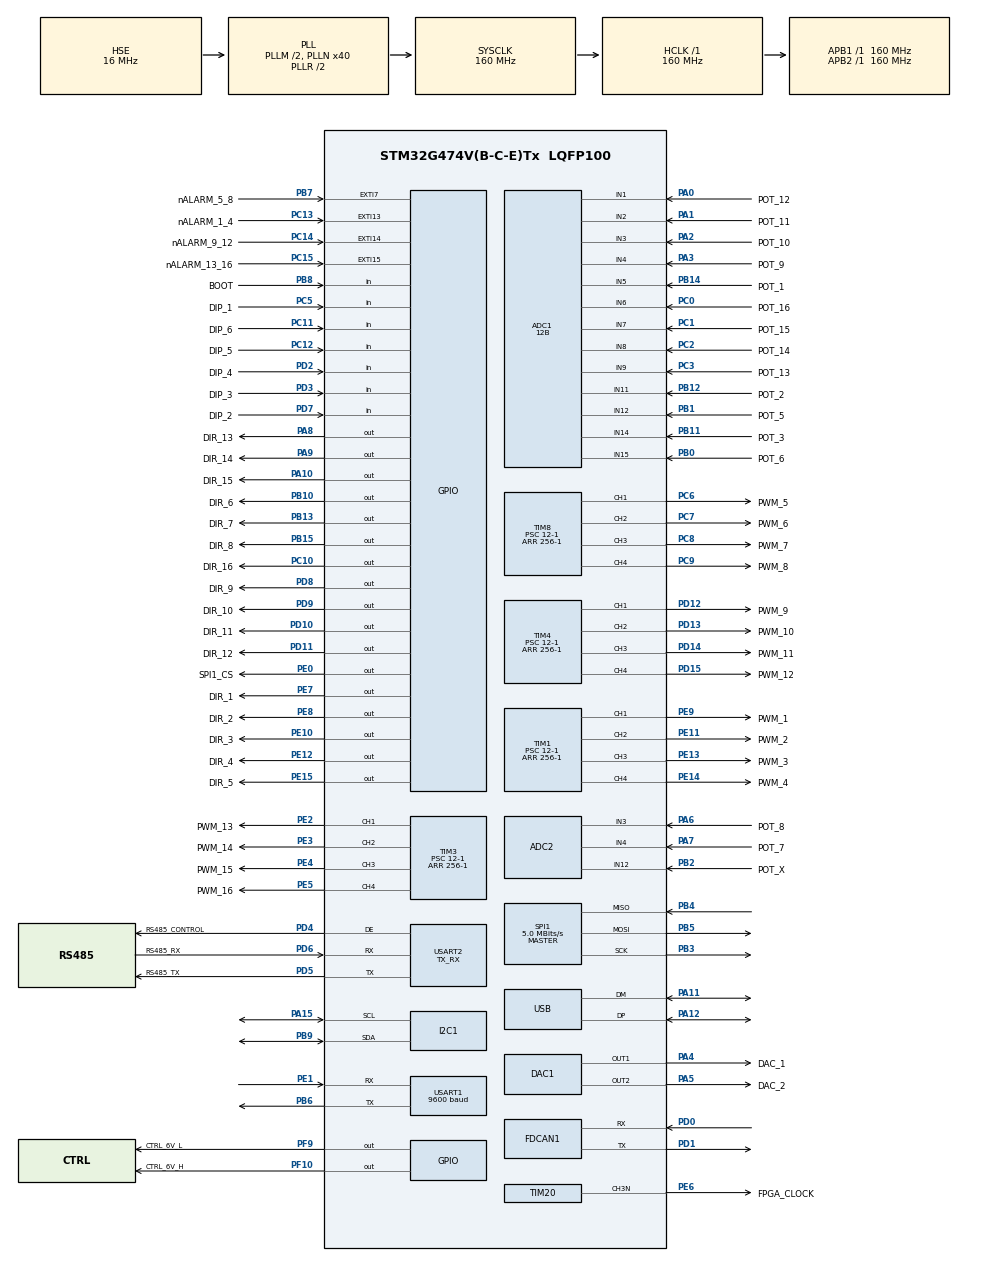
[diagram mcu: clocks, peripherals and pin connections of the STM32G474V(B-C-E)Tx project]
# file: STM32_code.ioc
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ADC1.Channel-0\#ChannelRegularConversion=ADC_CHANNEL_1
ADC1.Channel-1\#ChannelRegularConversion=ADC_CHANNEL_2
ADC1.Channel-10\#ChannelRegularConversion=ADC_CHANNEL_12
ADC1.Channel-11\#ChannelRegularConversion=ADC_CHANNEL_14
ADC1.Channel-12\#ChannelRegularConversion=ADC_CHANNEL_15
ADC1.Channel-2\#ChannelRegularConversion=ADC_CHANNEL_3
ADC1.Channel-3\#ChannelRegularConversion=ADC_CHANNEL_4
ADC1.Channel-4\#ChannelRegularConversion=ADC_CHANNEL_5
ADC1.Channel-5\#ChannelRegularConversion=ADC_CHANNEL_6
ADC1.Channel-6\#ChannelRegularConversion=ADC_CHANNEL_7
ADC1.Channel-7\#ChannelRegularConversion=ADC_CHANNEL_8
ADC1.Channel-8\#ChannelRegularConversion=ADC_CHANNEL_9
ADC1.Channel-9\#ChannelRegularConversion=ADC_CHANNEL_11
ADC1.ClockPrescaler=ADC_CLOCK_SYNC_PCLK_DIV4
ADC1.ContinuousConvMode=DISABLE
ADC1.DMAContinuousRequests=DISABLE
ADC1.EOCSelection=ADC_EOC_SEQ_CONV
ADC1.EnableInjectedConversion=DISABLE
ADC1.EnableRegularConversion=ENABLE
ADC1.NbrOfConversion=13
ADC1.NbrOfConversionFlag=1
ADC1.OffsetNumber-0\#ChannelRegularConversion=ADC_OFFSET_NONE
ADC1.OffsetNumber-1\#ChannelRegularConversion=ADC_OFFSET_NONE
ADC1.OffsetNumber-10\#ChannelRegularConversion=ADC_OFFSET_NONE
ADC1.OffsetNumber-11\#ChannelRegularConversion=ADC_OFFSET_NONE
ADC1.OffsetNumber-12\#ChannelRegularConversion=ADC_OFFSET_NONE
ADC1.OffsetNumber-2\#ChannelRegularConversion=ADC_OFFSET_NONE
ADC1.OffsetNumber-3\#ChannelRegularConversion=ADC_OFFSET_NONE
ADC1.OffsetNumber-4\#ChannelRegularConversion=ADC_OFFSET_NONE
ADC1.OffsetNumber-5\#ChannelRegularConversion=ADC_OFFSET_NONE
ADC1.OffsetNumber-6\#ChannelRegularConversion=ADC_OFFSET_NONE
ADC1.OffsetNumber-7\#ChannelRegularConversion=ADC_OFFSET_NONE
ADC1.OffsetNumber-8\#ChannelRegularConversion=ADC_OFFSET_NONE
ADC1.OffsetNumber-9\#ChannelRegularConversion=ADC_OFFSET_NONE
ADC1.Overrun=ADC_OVR_DATA_OVERWRITTEN
ADC1.Rank-0\#ChannelRegularConversion=1
ADC1.Rank-1\#ChannelRegularConversion=2
ADC1.Rank-10\#ChannelRegularConversion=11
ADC1.Rank-11\#ChannelRegularConversion=12
ADC1.Rank-12\#ChannelRegularConversion=13
ADC1.Rank-2\#ChannelRegularConversion=3
ADC1.Rank-3\#ChannelRegularConversion=4
ADC1.Rank-4\#ChannelRegularConversion=5
ADC1.Rank-5\#ChannelRegularConversion=6
ADC1.Rank-6\#ChannelRegularConversion=7
ADC1.Rank-7\#ChannelRegularConversion=8
ADC1.Rank-8\#ChannelRegularConversion=9
ADC1.Rank-9\#ChannelRegularConversion=10
ADC1.Resolution=ADC_RESOLUTION_12B
ADC1.SamplingTime-0\#ChannelRegularConversion=ADC_SAMPLETIME_24CYCLES_5
ADC1.SamplingTime-1\#ChannelRegularConversion=ADC_SAMPLETIME_24CYCLES_5
ADC1.SamplingTime-10\#ChannelRegularConversion=ADC_SAMPLETIME_24CYCLES_5
ADC1.SamplingTime-11\#ChannelRegularConversion=ADC_SAMPLETIME_24CYCLES_5
ADC1.SamplingTime-12\#ChannelRegularConversion=ADC_SAMPLETIME_24CYCLES_5
ADC1.SamplingTime-2\#ChannelRegularConversion=ADC_SAMPLETIME_24CYCLES_5
ADC1.SamplingTime-3\#ChannelRegularConversion=ADC_SAMPLETIME_24CYCLES_5
ADC1.SamplingTime-4\#ChannelRegularConversion=ADC_SAMPLETIME_24CYCLES_5
ADC1.SamplingTime-5\#ChannelRegularConversion=ADC_SAMPLETIME_24CYCLES_5
ADC1.SamplingTime-6\#ChannelRegularConversion=ADC_SAMPLETIME_24CYCLES_5
ADC1.SamplingTime-7\#ChannelRegularConversion=ADC_SAMPLETIME_24CYCLES_5
ADC1.SamplingTime-8\#ChannelRegularConversion=ADC_SAMPLETIME_24CYCLES_5
ADC1.SamplingTime-9\#ChannelRegularConversion=ADC_SAMPLETIME_24CYCLES_5
ADC1.master=1
ADC2.Channel-0\#ChannelRegularConversion=ADC_CHANNEL_3
ADC2.Channel-1\#ChannelRegularConversion=ADC_CHANNEL_4
ADC2.Channel-2\#ChannelRegularConversion=ADC_CHANNEL_12
ADC2.ClockPrescaler=ADC_CLOCK_SYNC_PCLK_DIV4
ADC2.ContinuousConvMode=DISABLE
ADC2.DMAContinuousRequests=DISABLE
ADC2.EOCSelection=ADC_EOC_SEQ_CONV
ADC2.NbrOfConversion=3
ADC2.NbrOfConversionFlag=1
ADC2.OffsetNumber-0\#ChannelRegularConversion=ADC_OFFSET_NONE
ADC2.OffsetNumber-1\#ChannelRegularConversion=ADC_OFFSET_NONE
ADC2.OffsetNumber-2\#ChannelRegularConversion=ADC_OFFSET_NONE
ADC2.Overrun=ADC_OVR_DATA_OVERWRITTEN
ADC2.Rank-0\#ChannelRegularConversion=1
ADC2.Rank-1\#ChannelRegularConversion=2
ADC2.Rank-2\#ChannelRegularConversion=3
ADC2.SamplingTime-0\#ChannelRegularConversion=ADC_SAMPLETIME_24CYCLES_5
ADC2.SamplingTime-1\#ChannelRegularConversion=ADC_SAMPLETIME_24CYCLES_5
ADC2.SamplingTime-2\#ChannelRegularConversion=ADC_SAMPLETIME_24CYCLES_5
DAC1.DAC_Channel-DAC_OUT2=DAC_CHANNEL_2
Dma.ADC1.0.Direction=DMA_PERIPH_TO_MEMORY
Dma.ADC1.0.EventEnable=DISABLE
Dma.ADC1.0.Instance=DMA1_Channel1
Dma.ADC1.0.MemDataAlignment=DMA_MDATAALIGN_HALFWORD
Dma.ADC1.0.MemInc=DMA_MINC_ENABLE
Dma.ADC1.0.Mode=DMA_NORMAL
Dma.ADC1.0.PeriphDataAlignment=DMA_PDATAALIGN_HALFWORD
Dma.ADC1.0.PeriphInc=DMA_PINC_DISABLE
Dma.ADC1.0.Polarity=HAL_DMAMUX_REQ_GEN_RISING
Dma.ADC1.0.Priority=DMA_PRIORITY_LOW
Dma.ADC1.0.RequestNumber=1
Dma.ADC1.0.SignalID=NONE
Dma.ADC1.0.SyncEnable=DISABLE
Dma.ADC1.0.SyncPolarity=HAL_DMAMUX_SYNC_NO_EVENT
Dma.ADC1.0.SyncRequestNumber=1
Dma.ADC1.0.SyncSignalID=NONE
Dma.ADC2.1.Direction=DMA_PERIPH_TO_MEMORY
Dma.ADC2.1.EventEnable=DISABLE
Dma.ADC2.1.Instance=DMA1_Channel2
Dma.ADC2.1.MemDataAlignment=DMA_MDATAALIGN_HALFWORD
Dma.ADC2.1.MemInc=DMA_MINC_ENABLE
Dma.ADC2.1.Mode=DMA_NORMAL
Dma.ADC2.1.PeriphDataAlignment=DMA_PDATAALIGN_HALFWORD
Dma.ADC2.1.PeriphInc=DMA_PINC_DISABLE
Dma.ADC2.1.Polarity=HAL_DMAMUX_REQ_GEN_RISING
Dma.ADC2.1.Priority=DMA_PRIORITY_LOW
Dma.ADC2.1.RequestNumber=1
Dma.ADC2.1.SignalID=NONE
Dma.ADC2.1.SyncEnable=DISABLE
Dma.ADC2.1.SyncPolarity=HAL_DMAMUX_SYNC_NO_EVENT
Dma.ADC2.1.SyncRequestNumber=1
Dma.ADC2.1.SyncSignalID=NONE
Dma.Request0=ADC1
Dma.Request1=ADC2
FDCAN1.AutoRetransmission=ENABLE
FDCAN1.CalculateBaudRateNominal=1000000
FDCAN1.CalculateTimeBitNominal=1000
FDCAN1.CalculateTimeQuantumNominal=62.5
FDCAN1.FrameFormat=FDCAN_FRAME_CLASSIC
FDCAN1.NominalPrescaler=10
FDCAN1.NominalTimeSeg1=13
FDCAN1.NominalTimeSeg2=2
FDCAN1.ProtocolException=ENABLE
I2C1.Timing=0x30D29DE4
Mcu.Family=STM32G4
Mcu.Name=STM32G474V(B-C-E)Tx
Mcu.Package=LQFP100
NVIC.DMA1_Channel1_IRQn=true\:0\:0\:false\:false\:true\:false\:true\:true
NVIC.DMA1_Channel2_IRQn=true\:0\:0\:false\:false\:true\:false\:true\:true
NVIC.EXTI15_10_IRQn=true\:0\:0\:false\:false\:true\:true\:true\:true
NVIC.EXTI9_5_IRQn=true\:0\:0\:false\:false\:true\:true\:true\:true
NVIC.FDCAN1_IT0_IRQn=true\:0\:0\:false\:false\:true\:true\:true\:true
NVIC.PriorityGroup=NVIC_PRIORITYGROUP_4
NVIC.USART1_IRQn=true\:0\:0\:false\:false\:true\:true\:true\:true
NVIC.USART2_IRQn=true\:0\:0\:false\:false\:true\:true\:true\:true
NVIC.USB_LP_IRQn=true\:0\:0\:true\:false\:true\:false\:true\:true
PA0.GPIO_Label=POT_12
PA0.Mode=IN1-Single-Ended
PA0.Signal=ADC1_IN1
PA1.GPIO_Label=POT_11
PA1.Mode=IN2-Single-Ended
PA1.Signal=ADC1_IN2
PA10.GPIO_Label=DIR_15
PA10.Signal=GPIO_Output
PA11.Mode=Device
PA11.Signal=USB_DM
PA12.Mode=Device
PA12.Signal=USB_DP
PA13.Mode=Serial_Wire
PA13.Signal=SYS_JTMS-SWDIO
PA14.Mode=Serial_Wire
PA14.Signal=SYS_JTCK-SWCLK
PA15.Mode=I2C
PA15.Signal=I2C1_SCL
PA2.GPIO_Label=POT_10
PA2.Mode=IN3-Single-Ended
PA2.Signal=ADC1_IN3
PA3.GPIO_Label=POT_9
PA3.Mode=IN4-Single-Ended
PA3.Signal=ADC1_IN4
PA4.GPIO_Label=DAC_1
PA4.Signal=COMP_DAC11_group
PA5.GPIO_Label=DAC_2
PA5.Signal=COMP_DAC12_group
PA6.GPIO_Label=POT_8
PA6.Mode=IN3-Single-Ended
PA6.Signal=ADC2_IN3
PA7.GPIO_Label=POT_7
PA7.Mode=IN4-Single-Ended
PA7.Signal=ADC2_IN4
PA8.GPIO_Label=DIR_13
PA8.Signal=GPIO_Output
PA9.GPIO_Label=DIR_14
PA9.Signal=GPIO_Output
PB0.GPIO_Label=POT_6
PB0.Mode=IN15-Single-Ended
PB0.Signal=ADC1_IN15
PB1.GPIO_Label=POT_5
PB1.Mode=IN12-Single-Ended
PB1.Signal=ADC1_IN12
PB10.GPIO_Label=DIR_6
PB10.Signal=GPIO_Output
PB11.GPIO_Label=POT_3
PB11.Mode=IN14-Single-Ended
PB11.Signal=ADC1_IN14
PB12.GPIO_Label=POT_2
PB12.Mode=IN11-Single-Ended
PB12.Signal=ADC1_IN11
PB13.GPIO_Label=DIR_7
PB13.Signal=GPIO_Output
PB14.GPIO_Label=POT_1
PB14.Mode=IN5-Single-Ended
PB14.Signal=ADC1_IN5
PB15.GPIO_Label=DIR_8
PB15.Signal=GPIO_Output
PB2.GPIO_Label=POT_X
PB2.Mode=IN12-Single-Ended
PB2.Signal=ADC2_IN12
PB3.Mode=Full_Duplex_Master
PB3.Signal=SPI1_SCK
PB4.Mode=Full_Duplex_Master
PB4.Signal=SPI1_MISO
PB5.Mode=Full_Duplex_Master
PB5.Signal=SPI1_MOSI
PB6.Mode=Asynchronous
PB6.Signal=USART1_TX
PB7.GPIO_Label=nALARM_5_8
PB7.Signal=GPXTI7
PB8-BOOT0.GPIO_Label=BOOT
PB8-BOOT0.Signal=GPIO_Input
PB9.Mode=I2C
PB9.Signal=I2C1_SDA
PC0.GPIO_Label=POT_16
PC0.Mode=IN6-Single-Ended
PC0.Signal=ADC1_IN6
PC1.GPIO_Label=POT_15
PC1.Mode=IN7-Single-Ended
PC1.Signal=ADC1_IN7
PC10.GPIO_Label=DIR_16
PC10.Signal=GPIO_Output
PC11.GPIO_Label=DIP_6
PC11.GPIO_PuPd=GPIO_PULLUP
PC11.Signal=GPIO_Input
PC12.GPIO_Label=DIP_5
PC12.GPIO_PuPd=GPIO_PULLUP
PC12.Signal=GPIO_Input
PC13.GPIO_Label=nALARM_1_4
PC13.Signal=GPXTI13
PC14-OSC32_IN.GPIO_Label=nALARM_9_12
PC14-OSC32_IN.Signal=GPXTI14
PC15-OSC32_OUT.GPIO_Label=nALARM_13_16
PC15-OSC32_OUT.Signal=GPXTI15
PC2.GPIO_Label=POT_14
PC2.Mode=IN8-Single-Ended
PC2.Signal=ADC1_IN8
PC3.GPIO_Label=POT_13
PC3.Mode=IN9-Single-Ended
PC3.Signal=ADC1_IN9
PC5.GPIO_Label=DIP_1
PC5.GPIO_PuPd=GPIO_PULLUP
PC5.Signal=GPIO_Input
PC6.GPIO_Label=PWM_5
PC6.Signal=S_TIM8_CH1
PC7.GPIO_Label=PWM_6
PC7.Signal=S_TIM8_CH2
PC8.GPIO_Label=PWM_7
PC8.Signal=S_TIM8_CH3
PC9.GPIO_Label=PWM_8
PC9.Signal=S_TIM8_CH4
PD0.Mode=FDCAN_Activate
PD0.Signal=FDCAN1_RX
PD1.Mode=FDCAN_Activate
PD1.Signal=FDCAN1_TX
PD10.GPIO_Label=DIR_11
PD10.Signal=GPIO_Output
PD11.GPIO_Label=DIR_12
PD11.Signal=GPIO_Output
PD12.GPIO_Label=PWM_9
PD12.Signal=S_TIM4_CH1
PD13.GPIO_Label=PWM_10
PD13.Signal=S_TIM4_CH2
PD14.GPIO_Label=PWM_11
PD14.Signal=S_TIM4_CH3
PD15.GPIO_Label=PWM_12
PD15.Signal=S_TIM4_CH4
PD2.GPIO_Label=DIP_4
PD2.GPIO_PuPd=GPIO_PULLUP
PD2.Signal=GPIO_Input
PD3.GPIO_Label=DIP_3
PD3.GPIO_PuPd=GPIO_PULLUP
PD3.Signal=GPIO_Input
PD4.GPIO_Label=RS485_CONTROL
PD4.Mode=Hardware Flow Control (RS485)
PD4.Signal=USART2_DE
PD5.GPIO_Label=RS485_TX
PD5.Mode=Asynchronous
PD5.Signal=USART2_TX
PD6.GPIO_Label=RS485_RX
PD6.Mode=Asynchronous
PD6.Signal=USART2_RX
PD7.GPIO_Label=DIP_2
PD7.GPIO_PuPd=GPIO_PULLUP
PD7.Signal=GPIO_Input
PD8.GPIO_Label=DIR_9
PD8.Signal=GPIO_Output
PD9.GPIO_Label=DIR_10
PD9.Signal=GPIO_Output
PE0.GPIO_Label=SPI1_CS
PE0.Signal=GPIO_Output
PE1.Mode=Asynchronous
PE1.Signal=USART1_RX
PE10.GPIO_Label=DIR_3
PE10.Signal=GPIO_Output
PE11.GPIO_Label=PWM_2
PE11.Signal=S_TIM1_CH2
PE12.GPIO_Label=DIR_4
PE12.Signal=GPIO_Output
PE13.GPIO_Label=PWM_3
PE13.Signal=S_TIM1_CH3
PE14.GPIO_Label=PWM_4
PE14.Signal=S_TIM1_CH4
PE15.GPIO_Label=DIR_5
PE15.Signal=GPIO_Output
PE2.GPIO_Label=PWM_13
PE2.Signal=S_TIM3_CH1
PE3.GPIO_Label=PWM_14
PE3.Signal=S_TIM3_CH2
PE4.GPIO_Label=PWM_15
PE4.Signal=S_TIM3_CH3
PE5.GPIO_Label=PWM_16
PE5.Signal=S_TIM3_CH4
PE6.GPIO_Label=FPGA_CLOCK
PE6.Mode=PWM Generation3 CH3N
PE6.Signal=TIM20_CH3N
PE7.GPIO_Label=DIR_1
PE7.Signal=GPIO_Output
PE8.GPIO_Label=DIR_2
PE8.Signal=GPIO_Output
PE9.GPIO_Label=PWM_1
PE9.Signal=S_TIM1_CH1
PF0-OSC_IN.Mode=HSE-External-Oscillator
PF0-OSC_IN.Signal=RCC_OSC_IN
PF1-OSC_OUT.Mode=HSE-External-Oscillator
PF1-OSC_OUT.Signal=RCC_OSC_OUT
PF10.GPIO_Label=CTRL_6V_H
PF10.Signal=GPIO_Output
PF9.GPIO_Label=CTRL_6V_L
PF9.Signal=GPIO_Output
ProjectManager.HeapSize=0x200
ProjectManager.StackSize=0x400
ProjectManager.TargetToolchain=STM32CubeIDE
RCC.ADC12Freq_Value=160000000
RCC.ADC345Freq_Value=160000000
RCC.AHBFreq_Value=160000000
RCC.APB1Freq_Value=160000000
RCC.APB1TimFreq_Value=160000000
RCC.APB2Freq_Value=160000000
RCC.APB2TimFreq_Value=160000000
RCC.CK48CLockSelection=RCC_USBCLKSOURCE_HSI48
RCC.CortexFreq_Value=160000000
RCC.EXTERNAL_CLOCK_VALUE=12288000
RCC.HCLKFreq_Value=160000000
RCC.HSE_VALUE=16000000
RCC.HSI48_VALUE=48000000
RCC.HSI_VALUE=16000000
RCC.LSE_VALUE=32768
RCC.PLLM=RCC_PLLM_DIV2
RCC.PLLN=40
RCC.PLLQ=RCC_PLLQ_DIV6
RCC.PLLSourceVirtual=RCC_PLLSOURCE_HSE
RCC.SYSCLKFreq_VALUE=160000000
RCC.SYSCLKSource=RCC_SYSCLKSOURCE_PLLCLK
RCC.USBFreq_Value=48000000
RCC.VCOOutputFreq_Value=320000000
SH.COMP_DAC11_group.0=DAC1_OUT1,DAC_OUT1
SH.COMP_DAC12_group.0=DAC1_OUT2,DAC_OUT2
SH.S_TIM1_CH1.0=TIM1_CH1,PWM Generation1 CH1
SH.S_TIM1_CH2.0=TIM1_CH2,PWM Generation2 CH2
SH.S_TIM1_CH3.0=TIM1_CH3,PWM Generation3 CH3
SH.S_TIM1_CH4.0=TIM1_CH4,PWM Generation4 CH4
SH.S_TIM3_CH1.0=TIM3_CH1,PWM Generation1 CH1
SH.S_TIM3_CH2.0=TIM3_CH2,PWM Generation2 CH2
SH.S_TIM3_CH3.0=TIM3_CH3,PWM Generation3 CH3
SH.S_TIM3_CH4.0=TIM3_CH4,PWM Generation4 CH4
SH.S_TIM4_CH1.0=TIM4_CH1,PWM Generation1 CH1
SH.S_TIM4_CH2.0=TIM4_CH2,PWM Generation2 CH2
SH.S_TIM4_CH3.0=TIM4_CH3,PWM Generation3 CH3
SH.S_TIM4_CH4.0=TIM4_CH4,PWM Generation4 CH4
SH.S_TIM8_CH1.0=TIM8_CH1,PWM Generation1 CH1
SH.S_TIM8_CH2.0=TIM8_CH2,PWM Generation2 CH2
SH.S_TIM8_CH3.0=TIM8_CH3,PWM Generation3 CH3
SH.S_TIM8_CH4.0=TIM8_CH4,PWM Generation4 CH4
SPI1.BaudRatePrescaler=SPI_BAUDRATEPRESCALER_32
SPI1.CalculateBaudRate=5.0 MBits/s
SPI1.Direction=SPI_DIRECTION_2LINES
SPI1.Mode=SPI_MODE_MASTER
SPI1.VirtualType=VM_MASTER
TIM1.AutoReloadPreload=TIM_AUTORELOAD_PRELOAD_ENABLE
TIM1.Channel-PWM\ Generation1\ CH1=TIM_CHANNEL_1
TIM1.Channel-PWM\ Generation2\ CH2=TIM_CHANNEL_2
TIM1.Channel-PWM\ Generation3\ CH3=TIM_CHANNEL_3
TIM1.Channel-PWM\ Generation4\ CH4=TIM_CHANNEL_4
TIM1.PeriodNoDither=256-1
TIM1.Prescaler=12-1
TIM2.Prescaler=160-1
TIM20.Channel-PWM\ Generation3\ CH3N=TIM_CHANNEL_3
TIM20.PeriodNoDither=4-1
TIM20.Prescaler=0
TIM20.PulseNoDither_3=2
TIM3.AutoReloadPreload=TIM_AUTORELOAD_PRELOAD_ENABLE
TIM3.Channel-PWM\ Generation1\ CH1=TIM_CHANNEL_1
TIM3.Channel-PWM\ Generation2\ CH2=TIM_CHANNEL_2
TIM3.Channel-PWM\ Generation3\ CH3=TIM_CHANNEL_3
TIM3.Channel-PWM\ Generation4\ CH4=TIM_CHANNEL_4
TIM3.PeriodNoDither=256-1
TIM3.Prescaler=12-1
TIM4.AutoReloadPreload=TIM_AUTORELOAD_PRELOAD_ENABLE
TIM4.Channel-PWM\ Generation1\ CH1=TIM_CHANNEL_1
TIM4.Channel-PWM\ Generation2\ CH2=TIM_CHANNEL_2
TIM4.Channel-PWM\ Generation3\ CH3=TIM_CHANNEL_3
TIM4.Channel-PWM\ Generation4\ CH4=TIM_CHANNEL_4
TIM4.PeriodNoDither=256-1
TIM4.Prescaler=12-1
TIM8.AutoReloadPreload=TIM_AUTORELOAD_PRELOAD_ENABLE
TIM8.Channel-PWM\ Generation1\ CH1=TIM_CHANNEL_1
TIM8.Channel-PWM\ Generation2\ CH2=TIM_CHANNEL_2
TIM8.Channel-PWM\ Generation3\ CH3=TIM_CHANNEL_3
TIM8.Channel-PWM\ Generation4\ CH4=TIM_CHANNEL_4
TIM8.PeriodNoDither=256-1
TIM8.Prescaler=12-1
USART1.BaudRate=9600
USART1.VirtualMode-Asynchronous=VM_ASYNC
USART2.Mode=MODE_TX_RX
USART2.VirtualMode-Asynchronous=VM_ASYNC
USART2.VirtualMode-Hardware\ Flow\ Control\ (RS485)=VM_ASYNC
USB_DEVICE.CLASS_NAME_FS=CDC
USB_DEVICE.VirtualMode=Cdc
USB_DEVICE.VirtualModeFS=Cdc_FS
VP_SYS_VS_DBSignals.Mode=DisableDeadBatterySignals
VP_TIM20_VS_ClockSourceINT.Mode=Internal
VP_TIM2_VS_ClockSourceINT.Mode=Internal
VP_USB_DEVICE_VS_USB_DEVICE_CDC_FS.Mode=CDC_FS
board=custom

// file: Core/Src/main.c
/* USER CODE BEGIN Header */
/**
  ******************************************************************************
  * @file           : main.c
  * @brief          : Main program body
  ******************************************************************************
  * @attention
  *
  * Copyright (c) 2025 STMicroelectronics.
  * All rights reserved.
  *
  * This software is licensed under terms that can be found in the LICENSE file
  * in the root directory of this software component.
  * If no LICENSE file comes with this software, it is provided AS-IS.
  *
  ******************************************************************************
  */
/* USER CODE END Header */
#include "main.h"
#include "adc.h"
#include "dac.h"
#include "dma.h"
#include "fdcan.h"
#include "i2c.h"
#include "spi.h"
#include "tim.h"
#include "usart.h"
#include "usb_device.h"
#include "gpio.h"

/* USER CODE BEGIN Includes */
#include "board_config.h"
#include "dip.h"
#include "timer_helper.h"
#include "can_helper.h"
#include "motor_helper.h"
#include "usb_debug.h"
/* USER CODE END Includes */

void SystemClock_Config(void);

int main(void)
{

  /* MCU Configuration--------------------------------------------------------*/

  /* Reset of all peripherals, Initializes the Flash interface and the Systick. */
  HAL_Init();

  /* Configure the system clock */
  SystemClock_Config();

  /* Initialize all configured peripherals */
  MX_GPIO_Init();
  MX_DMA_Init();
  MX_ADC1_Init();
  MX_DAC1_Init();
  MX_FDCAN1_Init();
  MX_I2C1_Init();
  MX_TIM1_Init();
  MX_TIM3_Init();
  MX_TIM4_Init();
  MX_TIM8_Init();
  MX_USART1_UART_Init();
  MX_USART2_UART_Init();
  MX_USB_Device_Init();
  MX_ADC2_Init();
  MX_TIM2_Init();
  MX_TIM20_Init();
  MX_SPI1_Init();
  /* USER CODE BEGIN 2 */
  board_id = Read_Board_ID();
  CAN_Configure_FD();
  HAL_FDCAN_Start(&hfdcan1);
  HAL_FDCAN_ActivateNotification(&hfdcan1, FDCAN_IT_RX_FIFO0_NEW_MESSAGE, ENABLE);
  Calibrate_ADC();
  HAL_TIM_Base_Start(&htim2);

  start_potentiometer_limits();
  motor_power_setup(1);
  motor_pwm_timers_start();

  /* USER CODE END 2 */

  /* Infinite loop */
  /* USER CODE BEGIN WHILE */
  position_init();
  uint32_t last_call = 0;
  while (1) {
    if (get_time_us() - last_call > 100) {
      last_call = get_time_us();
      control_loop();
      CAN_Check_Bus_Off();
    }
    /* USER CODE END WHILE */

  }
}

void SystemClock_Config(void)
{
  RCC_OscInitTypeDef RCC_OscInitStruct = {0};
  RCC_ClkInitTypeDef RCC_ClkInitStruct = {0};

  /** Configure the main internal regulator output voltage
  */
  HAL_PWREx_ControlVoltageScaling(PWR_REGULATOR_VOLTAGE_SCALE1_BOOST);

  /** Initializes the RCC Oscillators according to the specified parameters
  * in the RCC_OscInitTypeDef structure.
  */
  RCC_OscInitStruct.OscillatorType = RCC_OSCILLATORTYPE_HSI48|RCC_OSCILLATORTYPE_HSE;
  RCC_OscInitStruct.HSEState = RCC_HSE_ON;
  RCC_OscInitStruct.HSI48State = RCC_HSI48_ON;
  RCC_OscInitStruct.PLL.PLLState = RCC_PLL_ON;
  RCC_OscInitStruct.PLL.PLLSource = RCC_PLLSOURCE_HSE;
  RCC_OscInitStruct.PLL.PLLM = RCC_PLLM_DIV2;
  RCC_OscInitStruct.PLL.PLLN = 40;
  RCC_OscInitStruct.PLL.PLLP = RCC_PLLP_DIV2;
  RCC_OscInitStruct.PLL.PLLQ = RCC_PLLQ_DIV6;
  RCC_OscInitStruct.PLL.PLLR = RCC_PLLR_DIV2;
  if (HAL_RCC_OscConfig(&RCC_OscInitStruct) != HAL_OK)
  {
    Error_Handler();
  }

  /** Initializes the CPU, AHB and APB buses clocks
  */
  RCC_ClkInitStruct.ClockType = RCC_CLOCKTYPE_HCLK|RCC_CLOCKTYPE_SYSCLK
                              |RCC_CLOCKTYPE_PCLK1|RCC_CLOCKTYPE_PCLK2;
  RCC_ClkInitStruct.SYSCLKSource = RCC_SYSCLKSOURCE_PLLCLK;
  RCC_ClkInitStruct.AHBCLKDivider = RCC_SYSCLK_DIV1;
  RCC_ClkInitStruct.APB1CLKDivider = RCC_HCLK_DIV1;
  RCC_ClkInitStruct.APB2CLKDivider = RCC_HCLK_DIV1;

  if (HAL_RCC_ClockConfig(&RCC_ClkInitStruct, FLASH_LATENCY_4) != HAL_OK)
  {
    Error_Handler();
  }
}

void Error_Handler(void)
{
  __disable_irq();
  while (1)
  {
  }
}
